# EVE4_PRM register map
Vendor: Texas Instruments
Peripheral module from a debugger description file (folder TDA2Px).
Registers are 32-bit, access per field, reset 0x0 unless marked. A register's access mark holds for its fields unless they carry their own. Offsets are as the file gives them; lines under a group give offsets from that group; [hi:lo] are bit positions; {n}, {i} and the like mark numbered series; 'fields as' and 'values as' point back to an identical list; <NAME> marks a mode.

## EVE4_PRM
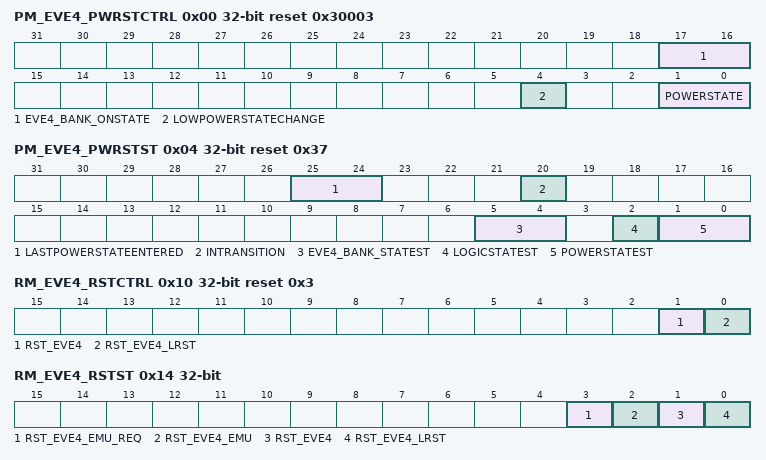
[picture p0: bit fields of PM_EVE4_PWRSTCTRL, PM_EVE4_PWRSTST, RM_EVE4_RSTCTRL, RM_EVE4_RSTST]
0x00 PM_EVE4_PWRSTCTRL reset 0x30003 — This register controls the EVE power state to reach upon a domain sleep transitionEVE4 is not supported in this family of devices.
  [17:16] EVE4_BANK_ONSTATE ro — EVE4 state when domain is ON.
    3=MEM_ON (Memory bank is on when the domain is ON.)
  [4] LOWPOWERSTATECHANGE rw — Power state change request when domain has already performed a sleep transition. Allows going into deeper low power state without waking up the power domain.
    0=DIS (Do not request a low power state change.); 1=EN (Request a low power state change. This bit is automatically cleared when the power state is effectively changed or when power state is ON.)
  [1:0] POWERSTATE rw — Power state control
    0=OFF (OFF state); 2=INACT (Reserved); 3=ON (ON State)
0x04 PM_EVE4_PWRSTST reset 0x37 — This register provides a status on the EVE domain current power state. [warm reset insensitive]EVE4 is not supported in this family of devices.
  [25:24] LASTPOWERSTATEENTERED rw — Last low power state entered. Set to 0x3 upon write of the same only. This register is intended for debug purpose only.
    0=OFF (Power domain was previously OFF); 1=RET (Reserved); 2=INACTIVE (Reserved); 3=ON (Power domain was previously ON-ACTIVE)
  [20] INTRANSITION ro — Domain transition status
    0=NO (No on-going transition on power domain); 1=ONGOING (Power domain transition is in progress.)
  [5:4] EVE4_BANK_STATEST ro — EVE4 memory state status
    0=MEM_OFF (Memory is OFF); 3=MEM_ON (Memory is ON)
  [2] LOGICSTATEST ro — Logic state status
    0=OFF (Reserved); 1=ON (Logic in domain is ON)
  [1:0] POWERSTATEST ro — Current power state status
    0=OFF (Power domain is OFF); 1=RET (Reserved); 2=INACTIVE (Reserved); 3=ON (Power domain is ON-ACTIVE)
0x10 RM_EVE4_RSTCTRL reset 0x3 — This register controls the release of the EVE sub-system resets.EVE4 is not supported in this family of devices.
  [1] RST_EVE4 rw — EVE SW reset control
    0=CLEAR (Reset is cleared); 1=ASSERT (Local Reset is asserted)
  [0] RST_EVE4_LRST rw — EVE4 Local reset control
    0=CLEAR (Reset is cleared for the DSP - DSP); 1=ASSERT (Reset is asserted for the DSP - DSP)
0x14 RM_EVE4_RSTST — This register logs the different reset sources of the EVE domain. Each bit is set upon release of the domain reset signal. Must be cleared by software. [warm reset insensitive]EVE4 is not supported in this family of devices.
  [3] RST_EVE4_EMU_REQ rw — EVE4 processor has been reset due to EVE emulation reset request driven from EVE4-SS
    0=RESET_NO (No emulation reset); 1=RESET_YES (EVE has been reset upon emulation reset request)
  [2] RST_EVE4_EMU rw — EVE4 domain has been reset due to emulation reset source e.g. assert reset command initiated by the icepick module
    0=RESET_NO (No emulation reset); 1=RESET_YES (EVE has been reset upon emulation reset)
  [1] RST_EVE4 rw — EVE4 SW reset status
    0=RESET_NO (No SW reset occurred); 1=RESET_YES (Local reset upon SW reset)
  [0] RST_EVE4_LRST rw — EVE4 Local SW reset
    0=RESET_NO (No SW reset occurred); 1=RESET_YES (EVE has been reset upon SW reset)
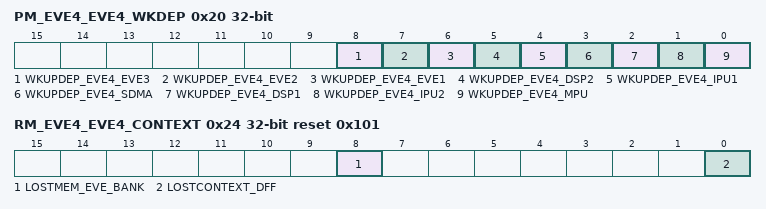
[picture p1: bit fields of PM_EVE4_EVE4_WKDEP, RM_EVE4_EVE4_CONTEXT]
0x20 PM_EVE4_EVE4_WKDEP — This register controls wakeup dependency based on EVE4 service requests.EVE4 is not supported in this family of devices.
  [8] WKUPDEP_EVE4_EVE3 rw — Wakeup dependency from EVE4 module (SWakeup signal) towards EVE3 + L3_MAIN1 + L4PER1 + L4PER2 + L4PER3 domains
    0=DISABLED (Dependency is disabled); 1=ENABLED (Dependency is enabled)
  [7] WKUPDEP_EVE4_EVE2 rw — Wakeup dependency from EVE4 module (SWakeup signal) towards EVE2 + L3_MAIN1 + L4PER1 + L4PER2 + L4PER3 domains
    values as WKUPDEP_EVE4_EVE3
  [6] WKUPDEP_EVE4_EVE1 rw — Wakeup dependency from EVE4 module (SWakeup signal) towards EVE1 + L3_MAIN1 + L4PER1 + L4PER2 + L4PER3 domains
    values as WKUPDEP_EVE4_EVE3
  [5] WKUPDEP_EVE4_DSP2 rw — Wakeup dependency from EVE4 module (SWakeup signal) towards DSP2 + L3_MAIN1 + L4PER1 + L4PER2 + L4PER3 domains
    values as WKUPDEP_EVE4_EVE3
  [4] WKUPDEP_EVE4_IPU1 rw — Wakeup dependency from EVE4 module (SWakeup signal) towards IPU1 + L3_MAIN1 + L4PER1 + L4PER2 + L4PER3 domains
    values as WKUPDEP_EVE4_EVE3
  [3] WKUPDEP_EVE4_SDMA rw — Wakeup dependency from EVE4 module (SWakeup signal) towards SDMA + L3MAIN1 + L4PER1 + L4PER2 + L4PER3 domains
    0=Dependency_is_disabled; 1=Dependency_is_enabled
  [2] WKUPDEP_EVE4_DSP1 rw — Wakeup dependency from EVE4 module (SWakeup signal) towards DSP1 + L3_MAIN1 + L4PER1 + L4PER2 + L4PER3 domains
    values as WKUPDEP_EVE4_EVE3
  [1] WKUPDEP_EVE4_IPU2 rw — Wakeup dependency from EVE4 module (SWakeup signal) towards IPU2 + L3_MAIN1 + L4PER1 + L4PER2 + L4PER3 domains
    0=Dependency_is_disabled; 1=Dependency_is_enabled
  [0] WKUPDEP_EVE4_MPU rw — Wakeup dependency from EVE4 module (SWakeup signal) towards MPU + L3_MAIN1 + L4PER1 + L4PER2 + L4PER3 domains
    values as WKUPDEP_EVE4_EVE3
0x24 RM_EVE4_EVE4_CONTEXT reset 0x101 — This register contains dedicated EVE context statuses. [warm reset insensitive]EVE4 is not supported in this family of devices.
  [8] LOSTMEM_EVE_BANK rw — Specify if memory-based context in EVE4 memory bank has been lost due to a previous power transition or other reset source.
    0=MAINTAINED (Context has been maintained); 1=LOST (Context has been lost)
  [0] LOSTCONTEXT_DFF rw — Specify if DFF-based context has been lost due to a previous power transition or other reset source. (set upon assertion of EVE1_SYS_RST signal)
    values as LOSTMEM_EVE_BANK
